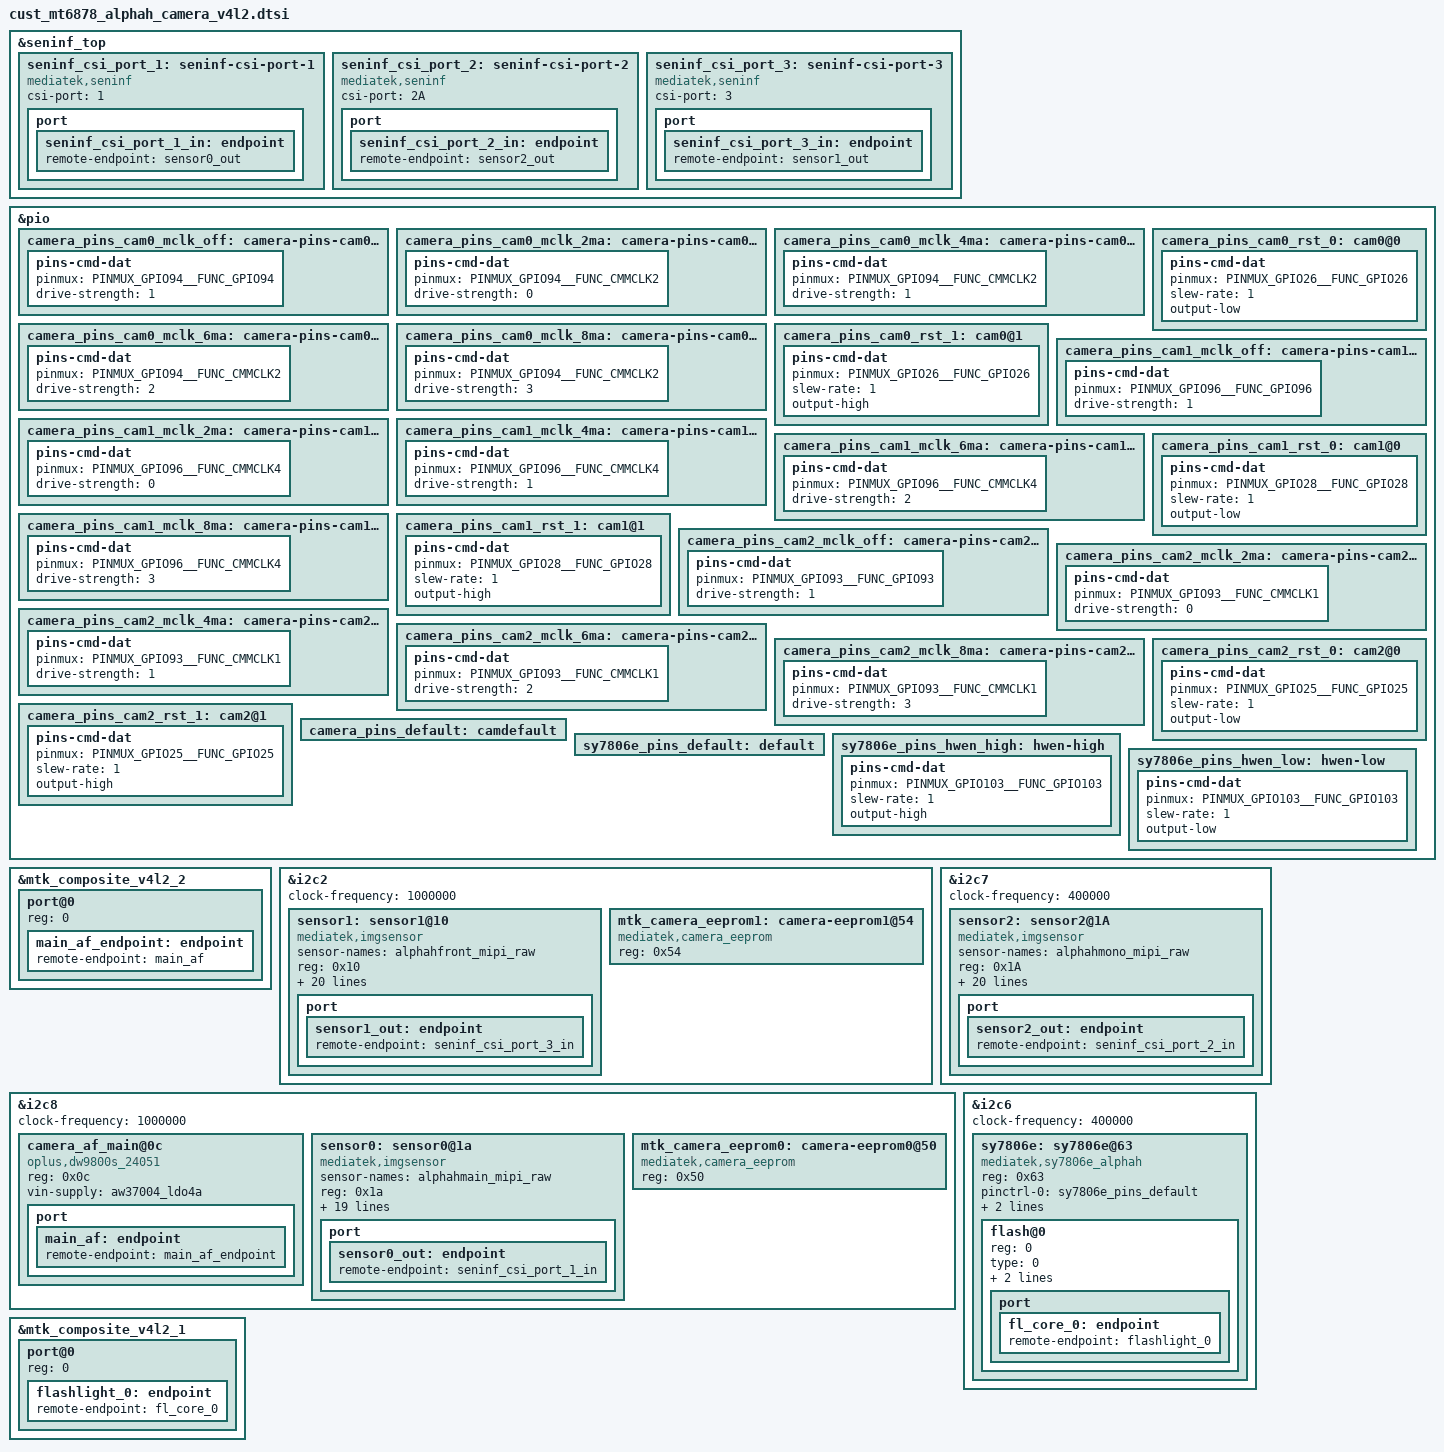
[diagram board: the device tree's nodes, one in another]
// SPDX-License-Identifier: GPL-2.0
/* Copyright (c) 2020 MediaTek Inc. */
#include <dt-bindings/clock/mt6878-clk.h>

&seninf_top {
		seninf_csi_port_1: seninf-csi-port-1 {
			compatible = "mediatek,seninf";
			csi-port = "1";
#if 0
			nvmem-cells = <&csi_efuse1>;
			nvmem-cell-names = "rg_csi";
#endif
			port {
				seninf_csi_port_1_in: endpoint {
					remote-endpoint = <&sensor0_out>;
				};
			};
		};

		seninf_csi_port_2: seninf-csi-port-2 {
			compatible = "mediatek,seninf";
			csi-port = "2A";
#if 0
			nvmem-cells = <&csi_efuse2>;
			nvmem-cell-names = "rg_csi";
#endif
			port {
				seninf_csi_port_2_in: endpoint {
					remote-endpoint = <&sensor2_out>;
				};
			};
		};
		seninf_csi_port_3: seninf-csi-port-3 {
			compatible = "mediatek,seninf";
			csi-port = "3";
#if 0
			nvmem-cells = <&csi_efuse3>;
			nvmem-cell-names = "rg_csi";
#endif
			port {
				seninf_csi_port_3_in: endpoint {
					remote-endpoint = <&sensor1_out>;
				};
			};
		};
};

/* CAMERA GPIO standardization */
&pio {
	camera_pins_cam0_mclk_off: camera-pins-cam0-mclk-off {
		pins-cmd-dat {
			pinmux = <PINMUX_GPIO94__FUNC_GPIO94>;
			drive-strength = <1>;
		};
	};
	camera_pins_cam0_mclk_2ma: camera-pins-cam0-mclk-2ma {
		pins-cmd-dat {
			pinmux = <PINMUX_GPIO94__FUNC_CMMCLK2>;
			drive-strength = <0>;
		};
	};
	camera_pins_cam0_mclk_4ma: camera-pins-cam0-mclk-4ma {
		pins-cmd-dat {
			pinmux = <PINMUX_GPIO94__FUNC_CMMCLK2>;
			drive-strength = <1>;
		};
	};
	camera_pins_cam0_mclk_6ma: camera-pins-cam0-mclk-6ma {
		pins-cmd-dat {
			pinmux = <PINMUX_GPIO94__FUNC_CMMCLK2>;
			drive-strength = <2>;
		};
	};
	camera_pins_cam0_mclk_8ma: camera-pins-cam0-mclk-8ma {
		pins-cmd-dat {
			pinmux = <PINMUX_GPIO94__FUNC_CMMCLK2>;
			drive-strength = <3>;
		};
	};
	camera_pins_cam0_rst_0: cam0@0 {
		pins-cmd-dat {
			pinmux = <PINMUX_GPIO26__FUNC_GPIO26>;
			slew-rate = <1>;
			output-low;
		};
	};
	camera_pins_cam0_rst_1: cam0@1 {
		pins-cmd-dat {
			pinmux = <PINMUX_GPIO26__FUNC_GPIO26>;
			slew-rate = <1>;
			output-high;
		};
	};
	camera_pins_cam1_mclk_off: camera-pins-cam1-mclk-off {
		pins-cmd-dat {
			pinmux = <PINMUX_GPIO96__FUNC_GPIO96>;
			drive-strength = <1>;
		};
	};
	camera_pins_cam1_mclk_2ma: camera-pins-cam1-mclk-2ma {
		pins-cmd-dat {
			pinmux = <PINMUX_GPIO96__FUNC_CMMCLK4>;
			drive-strength = <0>;
		};
	};
	camera_pins_cam1_mclk_4ma: camera-pins-cam1-mclk-4ma {
		pins-cmd-dat {
			pinmux = <PINMUX_GPIO96__FUNC_CMMCLK4>;
			drive-strength = <1>;
		};
	};
	camera_pins_cam1_mclk_6ma: camera-pins-cam1-mclk-6ma {
		pins-cmd-dat {
			pinmux = <PINMUX_GPIO96__FUNC_CMMCLK4>;
			drive-strength = <2>;
		};
	};
	camera_pins_cam1_mclk_8ma: camera-pins-cam1-mclk-8ma {
		pins-cmd-dat {
			pinmux = <PINMUX_GPIO96__FUNC_CMMCLK4>;
			drive-strength = <3>;
		};
	};
	camera_pins_cam1_rst_0: cam1@0 {
		pins-cmd-dat {
			pinmux = <PINMUX_GPIO28__FUNC_GPIO28>;
			slew-rate = <1>;
			output-low;
		};
	};
	camera_pins_cam1_rst_1: cam1@1 {
		pins-cmd-dat {
			pinmux = <PINMUX_GPIO28__FUNC_GPIO28>;
			slew-rate = <1>;
			output-high;
		};
	};
	camera_pins_cam2_mclk_off: camera-pins-cam2-mclk-off {
		pins-cmd-dat {
			pinmux = <PINMUX_GPIO93__FUNC_GPIO93>;
			drive-strength = <1>;
		};
	};
	camera_pins_cam2_mclk_2ma: camera-pins-cam2-mclk-2ma {
		pins-cmd-dat {
			pinmux = <PINMUX_GPIO93__FUNC_CMMCLK1>;
			drive-strength = <0>;
		};
	};
	camera_pins_cam2_mclk_4ma: camera-pins-cam2-mclk-4ma {
		pins-cmd-dat {
			pinmux = <PINMUX_GPIO93__FUNC_CMMCLK1>;
			drive-strength = <1>;
		};
	};
	camera_pins_cam2_mclk_6ma: camera-pins-cam2-mclk-6ma {
		pins-cmd-dat {
			pinmux = <PINMUX_GPIO93__FUNC_CMMCLK1>;
			drive-strength = <2>;
		};
	};
	camera_pins_cam2_mclk_8ma: camera-pins-cam2-mclk-8ma {
		pins-cmd-dat {
			pinmux = <PINMUX_GPIO93__FUNC_CMMCLK1>;
			drive-strength = <3>;
		};
	};
	camera_pins_cam2_rst_0: cam2@0 {
		pins-cmd-dat {
			pinmux = <PINMUX_GPIO25__FUNC_GPIO25>;
			slew-rate = <1>;
			output-low;
		};
	};
	camera_pins_cam2_rst_1: cam2@1 {
		pins-cmd-dat {
			pinmux = <PINMUX_GPIO25__FUNC_GPIO25>;
			slew-rate = <1>;
			output-high;
		};
	};
	camera_pins_default: camdefault {
	};
};
/* CAMERA GPIO end */

&mtk_composite_v4l2_2 {
	#address-cells = <1>;
	#size-cells = <0>;

	port@0 {
		reg = <0>;
		main_af_endpoint: endpoint {
			remote-endpoint = <&main_af>;
		};
	};
};


&i2c2 {
	status = "okay";
	clock-frequency = <1000000>;

	sensor1: sensor1@10 {
		compatible = "mediatek,imgsensor";
		sensor-names = "alphahfront_mipi_raw";
		reg = <0x10>;
		#reindex-to = <0>;
		#cust-aov-csi-clk = <312>;
		#thermal-sensor-cells = <0>;

		pinctrl-names = "mclk_off",
				"mclk_2mA",
				"mclk_4mA",
				"mclk_6mA",
				"mclk_8mA",
				"rst_low",
				"rst_high";

		pinctrl-0 = <&camera_pins_cam1_mclk_off>;
		pinctrl-1 = <&camera_pins_cam1_mclk_2ma>;
		pinctrl-2 = <&camera_pins_cam1_mclk_4ma>;
		pinctrl-3 = <&camera_pins_cam1_mclk_6ma>;
		pinctrl-4 = <&camera_pins_cam1_mclk_8ma>;
		pinctrl-5 = <&camera_pins_cam1_rst_0>;
		pinctrl-6 = <&camera_pins_cam1_rst_1>;

		avdd-supply = <&aw37004_ldo3a>;
		dvdd-supply = <&aw37004_ldo2a>;
		dovdd-supply = <&mt6369_vio28>;


		clocks = <&topckgen_clk CLK_TOP_UVPLL192M_D32>,
			<&topckgen_clk CLK_TOP_UVPLL192M_D16>,
			<&topckgen_clk CLK_TOP_OSC_D20>,
			<&topckgen_clk CLK_TOP_UVPLL192M_D10>,
			<&topckgen_clk CLK_TOP_UVPLL192M_D8>,
			<&topckgen_clk CLK_TOP_TCK_26M_MX9>,
			<&topckgen_clk CLK_TOP_UNIVPLL_D6_D8>,
			<&topckgen_clk CLK_TOP_CAMTG5_SEL>;
		clock-names = "6", "12", "13", "19.2", "24", "26", "52", "mclk";


		status = "okay";
		port {
			sensor1_out: endpoint {
				remote-endpoint = <&seninf_csi_port_3_in>;
			};
		};
	};
    mtk_camera_eeprom1:camera-eeprom1@54 {
		compatible = "mediatek,camera_eeprom";
		reg = <0x54>;
		status = "okay";
	};
};

&i2c7 {
	status = "okay";
	clock-frequency = <400000>;

    sensor2: sensor2@1A {
		compatible = "mediatek,imgsensor";
		sensor-names = "alphahmono_mipi_raw";
		reg = <0x1A>;
		#reindex-to = <0>;
		#cust-aov-csi-clk = <312>;
		#thermal-sensor-cells = <0>;

		pinctrl-names = "mclk_off",
				"mclk_2mA",
				"mclk_4mA",
				"mclk_6mA",
				"mclk_8mA",
				"rst_low",
				"rst_high";

		pinctrl-0 = <&camera_pins_cam2_mclk_off>;
		pinctrl-1 = <&camera_pins_cam2_mclk_2ma>;
		pinctrl-2 = <&camera_pins_cam2_mclk_4ma>;
		pinctrl-3 = <&camera_pins_cam2_mclk_6ma>;
		pinctrl-4 = <&camera_pins_cam2_mclk_8ma>;
		pinctrl-5 = <&camera_pins_cam2_rst_0>;
		pinctrl-6 = <&camera_pins_cam2_rst_1>;

		avdd-supply = <&aw37004_ldo3a>;
		dvdd-supply = <&mt6369_vio28>;
		dovdd-supply = <&mt6369_vio28>;

		clocks = <&topckgen_clk CLK_TOP_UVPLL192M_D32>,
			<&topckgen_clk CLK_TOP_UVPLL192M_D16>,
			<&topckgen_clk CLK_TOP_OSC_D20>,
			<&topckgen_clk CLK_TOP_UVPLL192M_D10>,
			<&topckgen_clk CLK_TOP_UVPLL192M_D8>,
			<&topckgen_clk CLK_TOP_TCK_26M_MX9>,
			<&topckgen_clk CLK_TOP_UNIVPLL_D6_D8>,
			<&topckgen_clk CLK_TOP_CAMTG2_SEL>;
		clock-names = "6", "12", "13", "19.2", "24", "26", "52", "mclk";

		status = "okay";
		port {
			sensor2_out: endpoint {
				remote-endpoint = <&seninf_csi_port_2_in>;
			};
		};
	};
};

&i2c8 {
	status = "okay";
	clock-frequency = <1000000>;

	camera_af_main@0c {
		compatible = "oplus,dw9800s_24051";
		reg = <0x0c>;
		vin-supply = <&aw37004_ldo4a>;
		port {
			main_af: endpoint {
				remote-endpoint = <&main_af_endpoint>;
			};
		};
	};

	sensor0: sensor0@1a {
		compatible = "mediatek,imgsensor";
		sensor-names = "alphahmain_mipi_raw";
		reg = <0x1a>;

		#thermal-sensor-cells = <0>;

		pinctrl-names = "mclk_off",
				"mclk_2mA",
				"mclk_4mA",
				"mclk_6mA",
				"mclk_8mA",
				"rst_low",
				"rst_high";
		pinctrl-0 = <&camera_pins_cam0_mclk_off>;
		pinctrl-1 = <&camera_pins_cam0_mclk_2ma>;
		pinctrl-2 = <&camera_pins_cam0_mclk_4ma>;
		pinctrl-3 = <&camera_pins_cam0_mclk_6ma>;
		pinctrl-4 = <&camera_pins_cam0_mclk_8ma>;
		pinctrl-5 = <&camera_pins_cam0_rst_0>;
		pinctrl-6 = <&camera_pins_cam0_rst_1>;

		avdd-supply = <&aw37004_ldo3a>;
        afvdd-supply = <&aw37004_ldo4a>;
		dvdd-supply = <&aw37004_ldo1a>;
		dovdd-supply = <&mt6369_vio28>;

		clocks = <&topckgen_clk CLK_TOP_UVPLL192M_D32>,
			<&topckgen_clk CLK_TOP_UVPLL192M_D16>,
			<&topckgen_clk CLK_TOP_OSC_D20>,
			<&topckgen_clk CLK_TOP_UVPLL192M_D10>,
			<&topckgen_clk CLK_TOP_UVPLL192M_D8>,
			<&topckgen_clk CLK_TOP_TCK_26M_MX9>,
			<&topckgen_clk CLK_TOP_UNIVPLL_D6_D8>,
			<&topckgen_clk CLK_TOP_CAMTG3_SEL>;
		clock-names = "6", "12", "13", "19.2", "24", "26", "52", "mclk";

		status = "okay";
		port {
			sensor0_out: endpoint {
				remote-endpoint = <&seninf_csi_port_1_in>;
			};
		};
	};

	mtk_camera_eeprom0:camera-eeprom0@50 {
		compatible = "mediatek,camera_eeprom";
		reg = <0x50>;
		status = "okay";
	};
};

&i2c6 {
	clock-frequency = <400000>;
	#address-cells = <1>;
	#size-cells = <0>;
	sy7806e:sy7806e@63 {
		compatible = "mediatek,sy7806e_alphah";
		#address-cells = <1>;
		#size-cells = <0>;
		reg = <0x63>;
		#cooling-cells = <2>;
		pinctrl-names = "default", "hwen-high", "hwen-low";
		pinctrl-0 = <&sy7806e_pins_default>;
		pinctrl-1 = <&sy7806e_pins_hwen_high>;
		pinctrl-2 = <&sy7806e_pins_hwen_low>;
		status = "okay";
		flash@0{
			reg = <0>;
			type = <0>;
			ct = <0>;
			part = <0>;
			port {
				fl_core_0: endpoint {
					remote-endpoint = <&flashlight_0>;
				};
			};
		};
	};
};

&pio {
	sy7806e_pins_default: default {
	};

	sy7806e_pins_hwen_high: hwen-high {
		pins-cmd-dat {
			pinmux = <PINMUX_GPIO103__FUNC_GPIO103>;
			slew-rate = <1>;
			output-high;
		};
	};

	sy7806e_pins_hwen_low: hwen-low {
		pins-cmd-dat {
			pinmux = <PINMUX_GPIO103__FUNC_GPIO103>;
			slew-rate = <1>;
			output-low;
		};
	};
};

&mtk_composite_v4l2_1 {
	#address-cells = <1>;
	#size-cells = <0>;
	port@0 {
		reg = <0>;
		flashlight_0: endpoint {
			remote-endpoint = <&fl_core_0>;
		};
	};
};
